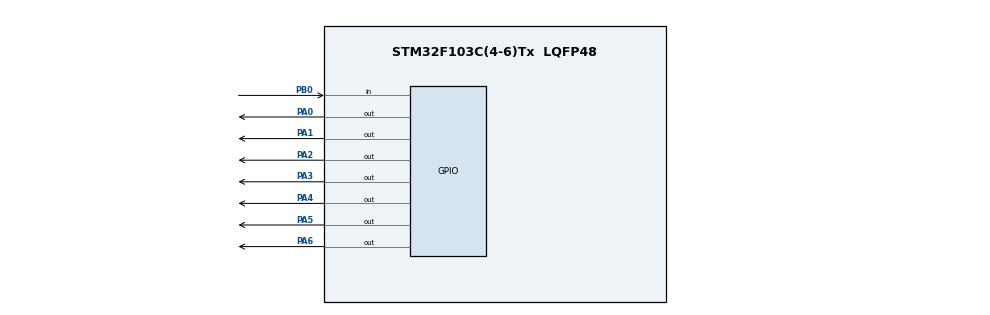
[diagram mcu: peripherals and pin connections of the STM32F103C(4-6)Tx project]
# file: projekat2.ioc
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Mcu.Family=STM32F1
Mcu.Name=STM32F103C(4-6)Tx
Mcu.Package=LQFP48
NVIC.PriorityGroup=NVIC_PRIORITYGROUP_4
PA0-WKUP.Signal=GPIO_Output
PA1.Signal=GPIO_Output
PA2.Signal=GPIO_Output
PA3.Signal=GPIO_Output
PA4.Signal=GPIO_Output
PA5.Signal=GPIO_Output
PA6.Signal=GPIO_Output
PB0.Signal=GPIO_Input
ProjectManager.HeapSize=0x200
ProjectManager.StackSize=0x400
ProjectManager.TargetToolchain=STM32CubeIDE
RCC.APB1Freq_Value=8000000
RCC.APB2Freq_Value=8000000
board=custom

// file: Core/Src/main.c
/* USER CODE BEGIN Header */
/**
  ******************************************************************************
  * @file           : main.c
  * @brief          : Main program body
  ******************************************************************************
  * @attention
  *
  * Copyright (c) 2022 STMicroelectronics.
  * All rights reserved.
  *
  * This software is licensed under terms that can be found in the LICENSE file
  * in the root directory of this software component.
  * If no LICENSE file comes with this software, it is provided AS-IS.
  *
  ******************************************************************************
  */
/* USER CODE END Header */
#include "main.h"
#include "math.h"

#define led0 GPIO_0
#define led1 GPIO_1
#define led2 GPIO_2
#define led3 GPIO_3
#define led4 GPIO_4
#define led5 GPIO_5
#define led6 GPIO_6
#define mojtaster GPIO_PIN_0

int values[] = {0x07, 0x4F};

void SystemClock_Config(void);
static void MX_GPIO_Init(void);

int main(void)
{
  /* USER CODE BEGIN 1 */
	int brojac = 0;
	int flag = 0;
	/* USER CODE END 1 */

  /* MCU Configuration--------------------------------------------------------*/

  /* Reset of all peripherals, Initializes the Flash interface and the Systick. */
  HAL_Init();

  /* Configure the system clock */
  SystemClock_Config();

  /* Initialize all configured peripherals */
  MX_GPIO_Init();

  /* Infinite loop */
  while (1)
  {
	  if(HAL_GPIO_ReadPin(GPIOB, mojtaster) == 1)
	  {
		  GPIOA->ODR = ~values[brojac%2];
		  flag = 1;
	  }
	  else
	  {
		  if(flag)
		  {
			  brojac++;
			  flag = 0;
		  }
	  }

  }
}

void SystemClock_Config(void)
{
  RCC_OscInitTypeDef RCC_OscInitStruct = {0};
  RCC_ClkInitTypeDef RCC_ClkInitStruct = {0};

  /** Initializes the RCC Oscillators according to the specified parameters
  * in the RCC_OscInitTypeDef structure.
  */
  RCC_OscInitStruct.OscillatorType = RCC_OSCILLATORTYPE_HSI;
  RCC_OscInitStruct.HSIState = RCC_HSI_ON;
  RCC_OscInitStruct.HSICalibrationValue = RCC_HSICALIBRATION_DEFAULT;
  RCC_OscInitStruct.PLL.PLLState = RCC_PLL_NONE;
  if (HAL_RCC_OscConfig(&RCC_OscInitStruct) != HAL_OK)
  {
    Error_Handler();
  }

  /** Initializes the CPU, AHB and APB buses clocks
  */
  RCC_ClkInitStruct.ClockType = RCC_CLOCKTYPE_HCLK|RCC_CLOCKTYPE_SYSCLK
                              |RCC_CLOCKTYPE_PCLK1|RCC_CLOCKTYPE_PCLK2;
  RCC_ClkInitStruct.SYSCLKSource = RCC_SYSCLKSOURCE_HSI;
  RCC_ClkInitStruct.AHBCLKDivider = RCC_SYSCLK_DIV1;
  RCC_ClkInitStruct.APB1CLKDivider = RCC_HCLK_DIV1;
  RCC_ClkInitStruct.APB2CLKDivider = RCC_HCLK_DIV1;

  if (HAL_RCC_ClockConfig(&RCC_ClkInitStruct, FLASH_LATENCY_0) != HAL_OK)
  {
    Error_Handler();
  }
}

static void MX_GPIO_Init(void)
{
  GPIO_InitTypeDef GPIO_InitStruct = {0};

  /* GPIO Ports Clock Enable */
  __HAL_RCC_GPIOA_CLK_ENABLE();
  __HAL_RCC_GPIOB_CLK_ENABLE();

  /*Configure GPIO pin Output Level */
  HAL_GPIO_WritePin(GPIOA, GPIO_PIN_0|GPIO_PIN_1|GPIO_PIN_2|GPIO_PIN_3
                          |GPIO_PIN_4|GPIO_PIN_5|GPIO_PIN_6, GPIO_PIN_SET);

  /*Configure GPIO pins : PA0 PA1 PA2 PA3
                           PA4 PA5 PA6 */
  GPIO_InitStruct.Pin = GPIO_PIN_0|GPIO_PIN_1|GPIO_PIN_2|GPIO_PIN_3
                          |GPIO_PIN_4|GPIO_PIN_5|GPIO_PIN_6;
  GPIO_InitStruct.Mode = GPIO_MODE_OUTPUT_PP;
  GPIO_InitStruct.Pull = GPIO_NOPULL;
  GPIO_InitStruct.Speed = GPIO_SPEED_FREQ_LOW;
  HAL_GPIO_Init(GPIOA, &GPIO_InitStruct);

  /*Configure GPIO pin : PB1 */
  GPIO_InitStruct.Pin = GPIO_PIN_1;
  GPIO_InitStruct.Mode = GPIO_MODE_INPUT;
  GPIO_InitStruct.Pull = GPIO_NOPULL;
  HAL_GPIO_Init(GPIOB, &GPIO_InitStruct);

}

void Error_Handler(void)
{
  __disable_irq();
  while (1)
  {
  }
}
